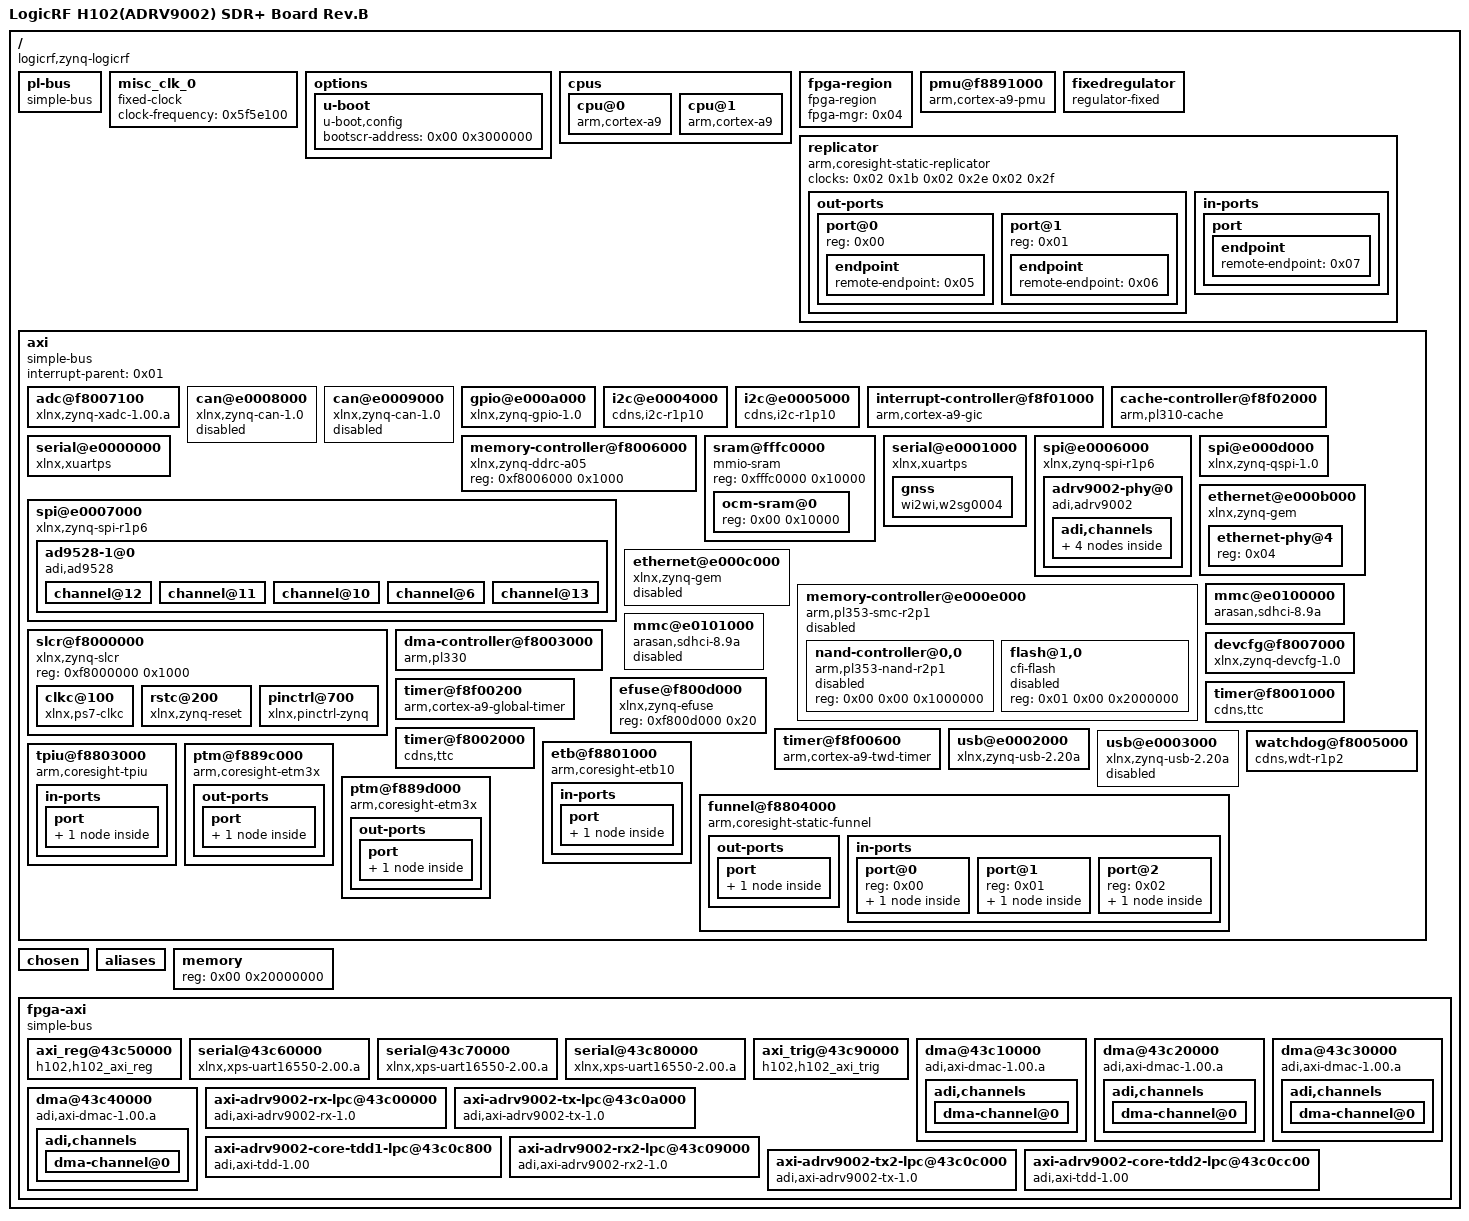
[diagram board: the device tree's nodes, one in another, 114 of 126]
/dts-v1/;

/ {
	#address-cells = <0x01>;
	#size-cells = <0x01>;
	compatible = "logicrf,zynq-logicrf\0xlnx,zynq-7000";
	model = "LogicRF H102(ADRV9002) SDR+ Board Rev.B";
	interrupt-parent = <0x01>;

	pl-bus {
		#address-cells = <0x01>;
		#size-cells = <0x01>;
		compatible = "simple-bus";
		ranges;
		phandle = <0x1b>;
	};

	misc_clk_0 {
		#clock-cells = <0x00>;
		clock-frequency = <0x5f5e100>;
		compatible = "fixed-clock";
		phandle = <0x15>;
	};

	options {

		u-boot {
			compatible = "u-boot,config";
			bootscr-address = <0x00 0x3000000>;
		};
	};

	cpus {
		#address-cells = <0x01>;
		#size-cells = <0x00>;

		cpu@0 {
			compatible = "arm,cortex-a9";
			device_type = "cpu";
			reg = <0x00>;
			clocks = <0x02 0x03>;
			clock-latency = <0x3e8>;
			cpu0-supply = <0x03>;
			operating-points = <0xa2c2b 0xf4240 0x51616 0xf4240>;
			phandle = <0x11>;
		};

		cpu@1 {
			compatible = "arm,cortex-a9";
			device_type = "cpu";
			reg = <0x01>;
			clocks = <0x02 0x03>;
			phandle = <0x13>;
		};
	};

	fpga-region {
		compatible = "fpga-region";
		fpga-mgr = <0x04>;
		#address-cells = <0x01>;
		#size-cells = <0x01>;
		ranges;
		phandle = <0x1c>;
	};

	pmu@f8891000 {
		compatible = "arm,cortex-a9-pmu";
		interrupts = <0x00 0x05 0x04 0x00 0x06 0x04>;
		interrupt-parent = <0x01>;
		reg = <0xf8891000 0x1000 0xf8893000 0x1000>;
	};

	fixedregulator {
		compatible = "regulator-fixed";
		regulator-name = "VCCPINT";
		regulator-min-microvolt = <0xf4240>;
		regulator-max-microvolt = <0xf4240>;
		regulator-boot-on;
		regulator-always-on;
		phandle = <0x03>;
	};

	replicator {
		compatible = "arm,coresight-static-replicator";
		clocks = <0x02 0x1b 0x02 0x2e 0x02 0x2f>;
		clock-names = "apb_pclk\0dbg_trc\0dbg_apb";

		out-ports {
			#address-cells = <0x01>;
			#size-cells = <0x00>;

			port@0 {
				reg = <0x00>;

				endpoint {
					remote-endpoint = <0x05>;
					phandle = <0x0d>;
				};
			};

			port@1 {
				reg = <0x01>;

				endpoint {
					remote-endpoint = <0x06>;
					phandle = <0x0c>;
				};
			};
		};

		in-ports {

			port {

				endpoint {
					remote-endpoint = <0x07>;
					phandle = <0x0e>;
				};
			};
		};
	};

	axi {
		bootph-all;
		compatible = "simple-bus";
		#address-cells = <0x01>;
		#size-cells = <0x01>;
		interrupt-parent = <0x01>;
		ranges;
		phandle = <0x1d>;

		adc@f8007100 {
			compatible = "xlnx,zynq-xadc-1.00.a";
			reg = <0xf8007100 0x20>;
			interrupts = <0x00 0x07 0x04>;
			interrupt-parent = <0x01>;
			clocks = <0x02 0x0c>;
			phandle = <0x1e>;
		};

		can@e0008000 {
			compatible = "xlnx,zynq-can-1.0";
			status = "disabled";
			clocks = <0x02 0x13 0x02 0x24>;
			clock-names = "can_clk\0pclk";
			reg = <0xe0008000 0x1000>;
			interrupts = <0x00 0x1c 0x04>;
			interrupt-parent = <0x01>;
			tx-fifo-depth = <0x40>;
			rx-fifo-depth = <0x40>;
			phandle = <0x1f>;
		};

		can@e0009000 {
			compatible = "xlnx,zynq-can-1.0";
			status = "disabled";
			clocks = <0x02 0x14 0x02 0x25>;
			clock-names = "can_clk\0pclk";
			reg = <0xe0009000 0x1000>;
			interrupts = <0x00 0x33 0x04>;
			interrupt-parent = <0x01>;
			tx-fifo-depth = <0x40>;
			rx-fifo-depth = <0x40>;
			phandle = <0x20>;
		};

		gpio@e000a000 {
			compatible = "xlnx,zynq-gpio-1.0";
			#gpio-cells = <0x02>;
			clocks = <0x02 0x2a>;
			gpio-controller;
			interrupt-controller;
			#interrupt-cells = <0x02>;
			interrupt-parent = <0x01>;
			interrupts = <0x00 0x14 0x04>;
			reg = <0xe000a000 0x1000>;
			emio-gpio-width = <0x40>;
			gpio-mask-high = <0x00>;
			gpio-mask-low = <0x5600>;
			phandle = <0x08>;
		};

		i2c@e0004000 {
			compatible = "cdns,i2c-r1p10";
			status = "okay";
			clocks = <0x02 0x26>;
			interrupt-parent = <0x01>;
			interrupts = <0x00 0x19 0x04>;
			clock-frequency = <0x61a80>;
			reg = <0xe0004000 0x1000>;
			#address-cells = <0x01>;
			#size-cells = <0x00>;
			phandle = <0x21>;
		};

		i2c@e0005000 {
			compatible = "cdns,i2c-r1p10";
			status = "okay";
			clocks = <0x02 0x27>;
			interrupt-parent = <0x01>;
			interrupts = <0x00 0x30 0x04>;
			clock-frequency = <0x61a80>;
			reg = <0xe0005000 0x1000>;
			#address-cells = <0x01>;
			#size-cells = <0x00>;
			phandle = <0x22>;
		};

		interrupt-controller@f8f01000 {
			compatible = "arm,cortex-a9-gic";
			#interrupt-cells = <0x03>;
			interrupt-controller;
			reg = <0xf8f01000 0x1000 0xf8f00100 0x100>;
			phandle = <0x01>;
		};

		cache-controller@f8f02000 {
			compatible = "arm,pl310-cache";
			reg = <0xf8f02000 0x1000>;
			interrupts = <0x00 0x02 0x04>;
			arm,data-latency = <0x03 0x02 0x02>;
			arm,tag-latency = <0x02 0x02 0x02>;
			cache-unified;
			cache-level = <0x02>;
			phandle = <0x23>;
		};

		memory-controller@f8006000 {
			compatible = "xlnx,zynq-ddrc-a05";
			reg = <0xf8006000 0x1000>;
			phandle = <0x24>;
		};

		sram@fffc0000 {
			compatible = "mmio-sram";
			reg = <0xfffc0000 0x10000>;
			#address-cells = <0x01>;
			#size-cells = <0x01>;
			ranges = <0x00 0xfffc0000 0x10000>;
			phandle = <0x25>;

			ocm-sram@0 {
				reg = <0x00 0x10000>;
			};
		};

		serial@e0000000 {
			compatible = "xlnx,xuartps\0cdns,uart-r1p8";
			status = "okay";
			clocks = <0x02 0x17 0x02 0x28>;
			clock-names = "uart_clk\0pclk";
			reg = <0xe0000000 0x1000>;
			interrupts = <0x00 0x1b 0x04>;
			cts-override;
			device_type = "serial";
			port-number = <0x04>;
			phandle = <0x26>;
		};

		serial@e0001000 {
			compatible = "xlnx,xuartps\0cdns,uart-r1p8";
			status = "okay";
			clocks = <0x02 0x18 0x02 0x29>;
			clock-names = "uart_clk\0pclk";
			reg = <0xe0001000 0x1000>;
			interrupts = <0x00 0x32 0x04>;
			cts-override;
			device_type = "serial";
			port-number = <0x05>;
			phandle = <0x27>;

			gnss {
				compatible = "wi2wi,w2sg0004";
				phandle = <0x28>;
			};
		};

		spi@e0006000 {
			compatible = "xlnx,zynq-spi-r1p6";
			reg = <0xe0006000 0x1000>;
			status = "okay";
			interrupt-parent = <0x01>;
			interrupts = <0x00 0x1a 0x04>;
			clocks = <0x02 0x19 0x02 0x22>;
			clock-names = "ref_clk\0pclk";
			#address-cells = <0x01>;
			#size-cells = <0x00>;
			is-decoded-cs = <0x00>;
			num-cs = <0x01>;
			phandle = <0x29>;

			adrv9002-phy@0 {
				compatible = "adi,adrv9002";
				reg = <0x00>;
				interrupt-parent = <0x08>;
				interrupts = <0x62 0x01>;
				spi-max-frequency = <0x1312d00>;
				clocks = <0x09 0x0c>;
				clock-names = "adrv9002_ext_refclk";
				clock-output-names = "rx1_sampl_clk\0tx1_sampl_clk\0tdd1_intf_clk\0rx2_sampl_clk\0tx2_sampl_clk\0tdd2_intf_clk";
				#clock-cells = <0x01>;
				reset-gpios = <0x08 0x64 0x01>;
				phandle = <0x16>;

				adi,channels {
					#address-cells = <0x01>;
					#size-cells = <0x00>;

					rx@0 {
						reg = <0x00>;
						adi,port = <0x00>;
						orx-gpios = <0x08 0x56 0x00>;
						phandle = <0x2a>;
					};

					rx@1 {
						reg = <0x01>;
						adi,port = <0x00>;
						orx-gpios = <0x08 0x57 0x00>;
						phandle = <0x2b>;
					};

					tx@0 {
						reg = <0x00>;
						adi,port = <0x01>;
					};

					tx@1 {
						reg = <0x01>;
						adi,port = <0x01>;
					};
				};
			};
		};

		spi@e0007000 {
			compatible = "xlnx,zynq-spi-r1p6";
			reg = <0xe0007000 0x1000>;
			status = "okay";
			interrupt-parent = <0x01>;
			interrupts = <0x00 0x31 0x04>;
			clocks = <0x02 0x1a 0x02 0x23>;
			clock-names = "ref_clk\0pclk";
			#address-cells = <0x01>;
			#size-cells = <0x00>;
			is-decoded-cs = <0x00>;
			num-cs = <0x03>;
			phandle = <0x2c>;

			ad9528-1@0 {
				compatible = "adi,ad9528";
				reg = <0x00>;
				#address-cells = <0x01>;
				#size-cells = <0x00>;
				spi-max-frequency = <0x989680>;
				clock-output-names = "ad9528-1_out0\0ad9528-1_out1\0ad9528-1_out2\0ad9528-1_out3\0ad9528-1_out4\0ad9528-1_out5\0ad9528-1_out6\0ad9528-1_out7\0ad9528-1_out8\0ad9528-1_out9\0ad9528-1_out10\0ad9528-1_out11\0ad9528-1_out12\0ad9528-1_out13";
				#clock-cells = <0x01>;
				adi,vcxo-freq = <0x5f5e100>;
				adi,refa-enable;
				adi,refa-diff-rcv-enable;
				adi,refa-r-div = <0x0a>;
				adi,refb-enable;
				adi,refb-r-div = <0x01>;
				adi,ref-mode = <0x03>;
				adi,pll1-feedback-div = <0x0a>;
				adi,pll1-charge-pump-current-nA = <0x1770>;
				adi,pll2-vco-div-m1 = <0x03>;
				adi,pll2-n2-div = <0x0c>;
				adi,pll2-r1-div = <0x01>;
				adi,pll2-charge-pump-current-nA = <0xda23c>;
				adi,sysref-src = <0x02>;
				adi,sysref-pattern-mode = <0x01>;
				adi,sysref-k-div = <0x200>;
				adi,sysref-request-enable;
				adi,sysref-nshot-mode = <0x03>;
				adi,sysref-request-trigger-mode = <0x00>;
				adi,rpole2 = <0x00>;
				adi,rzero = <0x07>;
				adi,cpole1 = <0x02>;
				adi,status-mon-pin0-function-select = <0x02>;
				adi,status-mon-pin1-function-select = <0x03>;
				reset-gpios = <0x08 0x65 0x00>;
				phandle = <0x09>;

				channel@12 {
					reg = <0x0c>;
					adi,extended-name = "DEV_CLK";
					adi,driver-mode = <0x00>;
					adi,divider-phase = <0x00>;
					adi,channel-divider = <0x04>;
					adi,signal-source = <0x00>;
					phandle = <0x2d>;
				};

				channel@11 {
					reg = <0x0b>;
					adi,extended-name = "MCS_CLK";
					adi,driver-mode = <0x00>;
					adi,divider-phase = <0x00>;
					adi,channel-divider = <0x04>;
					adi,signal-source = <0x02>;
					phandle = <0x2e>;
				};

				channel@10 {
					reg = <0x0a>;
					adi,extended-name = "FPGA_CLK";
					adi,driver-mode = <0x00>;
					adi,divider-phase = <0x00>;
					adi,channel-divider = <0x04>;
					adi,signal-source = <0x00>;
					phandle = <0x2f>;
				};

				channel@6 {
					reg = <0x06>;
					adi,extended-name = "FPGA_REFCLK";
					adi,driver-mode = <0x00>;
					adi,divider-phase = <0x00>;
					adi,channel-divider = <0x0c>;
					adi,signal-source = <0x00>;
					phandle = <0x30>;
				};

				channel@13 {
					reg = <0x0d>;
					adi,extended-name = "EXT_CLK";
					adi,driver-mode = <0x00>;
					adi,divider-phase = <0x00>;
					adi,channel-divider = <0x0c>;
					adi,signal-source = <0x00>;
					phandle = <0x31>;
				};
			};
		};

		spi@e000d000 {
			compatible = "xlnx,zynq-qspi-1.0";
			reg = <0xe000d000 0x1000>;
			interrupt-parent = <0x01>;
			interrupts = <0x00 0x13 0x04>;
			clocks = <0x02 0x0a 0x02 0x2b>;
			clock-names = "ref_clk\0pclk";
			status = "okay";
			#address-cells = <0x01>;
			#size-cells = <0x00>;
			is-dual = <0x01>;
			num-cs = <0x01>;
			spi-rx-bus-width = <0x08>;
			spi-tx-bus-width = <0x08>;
			phandle = <0x32>;
		};

		ethernet@e000b000 {
			compatible = "xlnx,zynq-gem\0cdns,gem";
			reg = <0xe000b000 0x1000>;
			status = "okay";
			interrupts = <0x00 0x16 0x04>;
			clocks = <0x02 0x1e 0x02 0x1e 0x02 0x0d>;
			clock-names = "pclk\0hclk\0tx_clk";
			#address-cells = <0x01>;
			#size-cells = <0x00>;
			enet-reset = <0x08 0x2e 0x00>;
			phy-mode = "rgmii-id";
			xlnx,ptp-enet-clock = <0x69f6bcb>;
			phy-handle = <0x0a>;
			phandle = <0x33>;

			ethernet-phy@4 {
				reg = <0x04>;
				phandle = <0x0a>;
			};
		};

		ethernet@e000c000 {
			compatible = "xlnx,zynq-gem\0cdns,gem";
			reg = <0xe000c000 0x1000>;
			status = "disabled";
			interrupts = <0x00 0x2d 0x04>;
			clocks = <0x02 0x1f 0x02 0x1f 0x02 0x0e>;
			clock-names = "pclk\0hclk\0tx_clk";
			#address-cells = <0x01>;
			#size-cells = <0x00>;
			phandle = <0x34>;
		};

		memory-controller@e000e000 {
			compatible = "arm,pl353-smc-r2p1\0arm,primecell";
			reg = <0xe000e000 0x1000>;
			status = "disabled";
			clock-names = "memclk\0apb_pclk";
			clocks = <0x02 0x0b 0x02 0x2c>;
			ranges = <0x00 0x00 0xe1000000 0x1000000 0x01 0x00 0xe2000000 0x2000000 0x02 0x00 0xe4000000 0x2000000>;
			#address-cells = <0x02>;
			#size-cells = <0x01>;
			interrupt-parent = <0x01>;
			interrupts = <0x00 0x12 0x04>;
			phandle = <0x35>;

			nand-controller@0,0 {
				compatible = "arm,pl353-nand-r2p1";
				reg = <0x00 0x00 0x1000000>;
				status = "disabled";
				phandle = <0x36>;
			};

			flash@1,0 {
				status = "disabled";
				compatible = "cfi-flash";
				reg = <0x01 0x00 0x2000000>;
				phandle = <0x37>;
			};
		};

		mmc@e0100000 {
			compatible = "arasan,sdhci-8.9a";
			status = "okay";
			clock-names = "clk_xin\0clk_ahb";
			clocks = <0x02 0x15 0x02 0x20>;
			interrupt-parent = <0x01>;
			interrupts = <0x00 0x18 0x04>;
			reg = <0xe0100000 0x1000>;
			xlnx,has-cd = <0x00>;
			xlnx,has-power = <0x00>;
			xlnx,has-wp = <0x00>;
			phandle = <0x38>;
		};

		mmc@e0101000 {
			compatible = "arasan,sdhci-8.9a";
			status = "disabled";
			clock-names = "clk_xin\0clk_ahb";
			clocks = <0x02 0x16 0x02 0x21>;
			interrupt-parent = <0x01>;
			interrupts = <0x00 0x2f 0x04>;
			reg = <0xe0101000 0x1000>;
			phandle = <0x39>;
		};

		slcr@f8000000 {
			bootph-all;
			#address-cells = <0x01>;
			#size-cells = <0x01>;
			compatible = "xlnx,zynq-slcr\0syscon\0simple-mfd";
			reg = <0xf8000000 0x1000>;
			ranges;
			phandle = <0x0b>;

			clkc@100 {
				bootph-all;
				#clock-cells = <0x01>;
				compatible = "xlnx,ps7-clkc";
				fclk-enable = <0x0f>;
				clock-output-names = "armpll\0ddrpll\0iopll\0cpu_6or4x\0cpu_3or2x\0cpu_2x\0cpu_1x\0ddr2x\0ddr3x\0dci\0lqspi\0smc\0pcap\0gem0\0gem1\0fclk0\0fclk1\0fclk2\0fclk3\0can0\0can1\0sdio0\0sdio1\0uart0\0uart1\0spi0\0spi1\0dma\0usb0_aper\0usb1_aper\0gem0_aper\0gem1_aper\0sdio0_aper\0sdio1_aper\0spi0_aper\0spi1_aper\0can0_aper\0can1_aper\0i2c0_aper\0i2c1_aper\0uart0_aper\0uart1_aper\0gpio_aper\0lqspi_aper\0smc_aper\0swdt\0dbg_trc\0dbg_apb";
				reg = <0x100 0x100>;
				ps-clk-frequency = <0x1fca055>;
				phandle = <0x02>;
			};

			rstc@200 {
				compatible = "xlnx,zynq-reset";
				reg = <0x200 0x48>;
				#reset-cells = <0x01>;
				syscon = <0x0b>;
				phandle = <0x3a>;
			};

			pinctrl@700 {
				compatible = "xlnx,pinctrl-zynq";
				reg = <0x700 0x200>;
				syscon = <0x0b>;
				phandle = <0x3b>;
			};
		};

		dma-controller@f8003000 {
			compatible = "arm,pl330\0arm,primecell";
			reg = <0xf8003000 0x1000>;
			interrupt-parent = <0x01>;
			interrupts = <0x00 0x0d 0x04 0x00 0x0e 0x04 0x00 0x0f 0x04 0x00 0x10 0x04 0x00 0x11 0x04 0x00 0x28 0x04 0x00 0x29 0x04 0x00 0x2a 0x04 0x00 0x2b 0x04>;
			#dma-cells = <0x01>;
			clocks = <0x02 0x1b>;
			clock-names = "apb_pclk";
			phandle = <0x3c>;
		};

		devcfg@f8007000 {
			compatible = "xlnx,zynq-devcfg-1.0";
			reg = <0xf8007000 0x100>;
			interrupt-parent = <0x01>;
			interrupts = <0x00 0x08 0x04>;
			clocks = <0x02 0x0c 0x02 0x0f 0x02 0x10 0x02 0x11 0x02 0x12>;
			clock-names = "ref_clk\0fclk0\0fclk1\0fclk2\0fclk3";
			syscon = <0x0b>;
			phandle = <0x04>;
		};

		efuse@f800d000 {
			compatible = "xlnx,zynq-efuse";
			reg = <0xf800d000 0x20>;
			phandle = <0x3d>;
		};

		timer@f8f00200 {
			compatible = "arm,cortex-a9-global-timer";
			reg = <0xf8f00200 0x20>;
			interrupts = <0x01 0x0b 0x301>;
			interrupt-parent = <0x01>;
			clocks = <0x02 0x04>;
			phandle = <0x3e>;
		};

		timer@f8001000 {
			interrupt-parent = <0x01>;
			interrupts = <0x00 0x0a 0x04 0x00 0x0b 0x04 0x00 0x0c 0x04>;
			compatible = "cdns,ttc";
			clocks = <0x02 0x06>;
			reg = <0xf8001000 0x1000>;
			phandle = <0x3f>;
		};

		timer@f8002000 {
			interrupt-parent = <0x01>;
			interrupts = <0x00 0x25 0x04 0x00 0x26 0x04 0x00 0x27 0x04>;
			compatible = "cdns,ttc";
			clocks = <0x02 0x06>;
			reg = <0xf8002000 0x1000>;
			phandle = <0x40>;
		};

		timer@f8f00600 {
			bootph-all;
			interrupt-parent = <0x01>;
			interrupts = <0x01 0x0d 0x301>;
			compatible = "arm,cortex-a9-twd-timer";
			reg = <0xf8f00600 0x20>;
			clocks = <0x02 0x04>;
			phandle = <0x41>;
		};

		usb@e0002000 {
			compatible = "xlnx,zynq-usb-2.20a\0chipidea,usb2";
			status = "okay";
			clocks = <0x02 0x1c>;
			interrupt-parent = <0x01>;
			interrupts = <0x00 0x15 0x04>;
			reg = <0xe0002000 0x1000>;
			phy_type = "ulpi";
			usb-reset = <0x08 0x2f 0x00>;
			phandle = <0x42>;
		};

		usb@e0003000 {
			compatible = "xlnx,zynq-usb-2.20a\0chipidea,usb2";
			status = "disabled";
			clocks = <0x02 0x1d>;
			interrupt-parent = <0x01>;
			interrupts = <0x00 0x2c 0x04>;
			reg = <0xe0003000 0x1000>;
			phy_type = "ulpi";
			phandle = <0x43>;
		};

		watchdog@f8005000 {
			clocks = <0x02 0x2d>;
			compatible = "cdns,wdt-r1p2";
			interrupt-parent = <0x01>;
			interrupts = <0x00 0x09 0x01>;
			reg = <0xf8005000 0x1000>;
			timeout-sec = <0x0a>;
			phandle = <0x44>;
		};

		etb@f8801000 {
			compatible = "arm,coresight-etb10\0arm,primecell";
			reg = <0xf8801000 0x1000>;
			clocks = <0x02 0x1b 0x02 0x2e 0x02 0x2f>;
			clock-names = "apb_pclk\0dbg_trc\0dbg_apb";

			in-ports {

				port {

					endpoint {
						remote-endpoint = <0x0c>;
						phandle = <0x06>;
					};
				};
			};
		};

		tpiu@f8803000 {
			compatible = "arm,coresight-tpiu\0arm,primecell";
			reg = <0xf8803000 0x1000>;
			clocks = <0x02 0x1b 0x02 0x2e 0x02 0x2f>;
			clock-names = "apb_pclk\0dbg_trc\0dbg_apb";

			in-ports {

				port {

					endpoint {
						remote-endpoint = <0x0d>;
						phandle = <0x05>;
					};
				};
			};
		};

		funnel@f8804000 {
			compatible = "arm,coresight-static-funnel\0arm,primecell";
			reg = <0xf8804000 0x1000>;
			clocks = <0x02 0x1b 0x02 0x2e 0x02 0x2f>;
			clock-names = "apb_pclk\0dbg_trc\0dbg_apb";

			out-ports {

				port {

					endpoint {
						remote-endpoint = <0x0e>;
						phandle = <0x07>;
					};
				};
			};

			in-ports {
				#address-cells = <0x01>;
				#size-cells = <0x00>;

				port@0 {
					reg = <0x00>;

					endpoint {
						remote-endpoint = <0x0f>;
						phandle = <0x12>;
					};
				};

				port@1 {
					reg = <0x01>;

					endpoint {
						remote-endpoint = <0x10>;
						phandle = <0x14>;
					};
				};

				port@2 {
					reg = <0x02>;

					endpoint {
						phandle = <0x45>;
					};
				};
			};
		};

		ptm@f889c000 {
			compatible = "arm,coresight-etm3x\0arm,primecell";
			reg = <0xf889c000 0x1000>;
			clocks = <0x02 0x1b 0x02 0x2e 0x02 0x2f>;
			clock-names = "apb_pclk\0dbg_trc\0dbg_apb";
			cpu = <0x11>;

			out-ports {

				port {

					endpoint {
						remote-endpoint = <0x12>;
						phandle = <0x0f>;
					};
				};
			};
		};

		ptm@f889d000 {
			compatible = "arm,coresight-etm3x\0arm,primecell";
			reg = <0xf889d000 0x1000>;
			clocks = <0x02 0x1b 0x02 0x2e 0x02 0x2f>;
			clock-names = "apb_pclk\0dbg_trc\0dbg_apb";
			cpu = <0x13>;

			out-ports {

				port {

					endpoint {
						remote-endpoint = <0x14>;
						phandle = <0x10>;
					};
				};
			};
		};
	};

	chosen {
		bootargs = "console=ttyPS0,115200 earlycon root=/dev/mmcblk0p2 ro rootwait";
		stdout-path = "serial0:115200n8";
	};

	aliases {
		ethernet0 = "/axi/ethernet@e000b000";
		i2c0 = "/axi/i2c@e0004000";
		i2c1 = "/axi/i2c@e0005000";
		serial0 = "/axi/serial@e0000000";
		serial1 = "/axi/serial@e0001000";
		serial2 = "/fpga-axi/serial@43c60000";
		serial3 = "/fpga-axi/serial@43c70000";
		serial4 = "/fpga-axi/serial@43c80000";
		spi0 = "/axi/spi@e000d000";
		spi1 = "/axi/spi@e0006000";
		spi2 = "/axi/spi@e0007000";
	};

	memory {
		device_type = "memory";
		reg = <0x00 0x20000000>;
	};

	fpga-axi {
		compatible = "simple-bus";
		#address-cells = <0x01>;
		#size-cells = <0x01>;
		ranges;
		phandle = <0x46>;

		axi_reg@43c50000 {
			clock-names = "s00_axi_aclk";
			clocks = <0x02 0x0f>;
			compatible = "h102,h102_axi_reg";
			reg = <0x43c50000 0x10000>;
			xlnx,s00-axi-addr-width = <0x0c>;
			xlnx,s00-axi-data-width = <0x20>;
			phandle = <0x47>;
		};

		serial@43c60000 {
			clock-frequency = <0x5f5e100>;
			clock-names = "s_axi_aclk";
			clocks = <0x02 0x0f>;
			compatible = "xlnx,xps-uart16550-2.00.a\0ns16550a";
			current-speed = <0x1c200>;
			device_type = "serial";
			interrupt-names = "ip2intc_irpt";
			interrupt-parent = <0x01>;
			interrupts = <0x00 0x21 0x04>;
			port-number = <0x00>;
			reg = <0x43c60000 0x10000>;
			reg-offset = <0x1000>;
			reg-shift = <0x02>;
			xlnx,external-xin-clk-hz = <0x17d7840>;
			xlnx,external-xin-clk-hz-d = <0x19>;
			xlnx,has-external-rclk = <0x00>;
			xlnx,has-external-xin = <0x00>;
			xlnx,is-a-16550 = <0x01>;
			xlnx,s-axi-aclk-freq-hz-d = "100.0";
			xlnx,sim-device = "VERSAL_AI_CORE_ES1";
			xlnx,use-modem-ports = <0x01>;
			xlnx,use-user-ports = <0x01>;
			phandle = <0x48>;
		};

		serial@43c70000 {
			clock-frequency = <0x5f5e100>;
			clock-names = "s_axi_aclk";
			clocks = <0x02 0x0f>;
			compatible = "xlnx,xps-uart16550-2.00.a\0ns16550a";
			current-speed = <0x1c200>;
			device_type = "serial";
			interrupt-names = "ip2intc_irpt";
			interrupt-parent = <0x01>;
			interrupts = <0x00 0x22 0x04>;
			port-number = <0x02>;
			reg = <0x43c70000 0x10000>;
			reg-offset = <0x1000>;
			reg-shift = <0x02>;
			xlnx,external-xin-clk-hz = <0x17d7840>;
			xlnx,external-xin-clk-hz-d = <0x19>;
			xlnx,has-external-rclk = <0x00>;
			xlnx,has-external-xin = <0x00>;
			xlnx,is-a-16550 = <0x01>;
			xlnx,s-axi-aclk-freq-hz-d = "100.0";
			xlnx,sim-device = "VERSAL_AI_CORE_ES1";
			xlnx,use-modem-ports = <0x01>;
			xlnx,use-user-ports = <0x01>;
			phandle = <0x49>;
		};

		serial@43c80000 {
			clock-frequency = <0x5f5e100>;
			clock-names = "s_axi_aclk";
			clocks = <0x02 0x0f>;
			compatible = "xlnx,xps-uart16550-2.00.a\0ns16550a";
			current-speed = <0x1c200>;
			device_type = "serial";
			interrupt-names = "ip2intc_irpt";
			interrupt-parent = <0x01>;
			interrupts = <0x00 0x23 0x04>;
			port-number = <0x03>;
			reg = <0x43c80000 0x10000>;
			reg-offset = <0x1000>;
			reg-shift = <0x02>;
			xlnx,external-xin-clk-hz = <0x17d7840>;
			xlnx,external-xin-clk-hz-d = <0x19>;
			xlnx,has-external-rclk = <0x00>;
			xlnx,has-external-xin = <0x00>;
			xlnx,is-a-16550 = <0x01>;
			xlnx,s-axi-aclk-freq-hz-d = "100.0";
			xlnx,sim-device = "VERSAL_AI_CORE_ES1";
			xlnx,use-modem-ports = <0x01>;
			xlnx,use-user-ports = <0x01>;
			phandle = <0x4a>;
		};

		axi_trig@43c90000 {
			clock-names = "s00_axi_aclk";
			clocks = <0x02 0x0f>;
			compatible = "h102,h102_axi_trig";
			reg = <0x43c90000 0x10000>;
			xlnx,s00-axi-addr-width = <0x0c>;
			xlnx,s00-axi-data-width = <0x20>;
			phandle = <0x4b>;
		};

		dma@43c10000 {
			compatible = "adi,axi-dmac-1.00.a";
			reg = <0x43c10000 0x10000>;
			#dma-cells = <0x01>;
			interrupts = <0x00 0x1d 0x04>;
			clock-names = "s_axi_aclk\0m_dest_axi_aclk\0fifo_wr_clk";
			clocks = <0x02 0x0f 0x02 0x10 0x15>;
			phandle = <0x17>;

			adi,channels {
				#size-cells = <0x00>;
				#address-cells = <0x01>;

				dma-channel@0 {
					reg = <0x00>;
					adi,source-bus-width = <0x40>;
					adi,source-bus-type = <0x02>;
					adi,destination-bus-width = <0x40>;
					adi,destination-bus-type = <0x00>;
				};
			};
		};

		dma@43c20000 {
			compatible = "adi,axi-dmac-1.00.a";
			reg = <0x43c20000 0x10000>;
			#dma-cells = <0x01>;
			interrupts = <0x00 0x1e 0x04>;
			clock-names = "s_axi_aclk\0m_dest_axi_aclk\0fifo_wr_clk";
			clocks = <0x02 0x0f 0x02 0x10 0x15>;
			phandle = <0x19>;

			adi,channels {
				#size-cells = <0x00>;
				#address-cells = <0x01>;

				dma-channel@0 {
					reg = <0x00>;
					adi,source-bus-width = <0x40>;
					adi,source-bus-type = <0x02>;
					adi,destination-bus-width = <0x40>;
					adi,destination-bus-type = <0x00>;
				};
			};
		};

		dma@43c30000 {
			compatible = "adi,axi-dmac-1.00.a";
			reg = <0x43c30000 0x10000>;
			#dma-cells = <0x01>;
			interrupts = <0x00 0x1f 0x04>;
			clock-names = "s_axi_aclk\0m_src_axi_aclk\0m_axis_aclk";
			clocks = <0x02 0x0f 0x02 0x10 0x15>;
			phandle = <0x18>;

			adi,channels {
				#size-cells = <0x00>;
				#address-cells = <0x01>;

				dma-channel@0 {
					reg = <0x00>;
					adi,source-bus-width = <0x40>;
					adi,source-bus-type = <0x00>;
					adi,destination-bus-width = <0x40>;
					adi,destination-bus-type = <0x02>;
				};
			};
		};

		dma@43c40000 {
			compatible = "adi,axi-dmac-1.00.a";
			reg = <0x43c40000 0x10000>;
			#dma-cells = <0x01>;
			interrupts = <0x00 0x20 0x04>;
			clock-names = "s_axi_aclk\0m_src_axi_aclk\0m_axis_aclk";
			clocks = <0x02 0x0f 0x02 0x10 0x15>;
			phandle = <0x1a>;

			adi,channels {
				#size-cells = <0x00>;
				#address-cells = <0x01>;

				dma-channel@0 {
					reg = <0x00>;
					adi,source-bus-width = <0x40>;
					adi,source-bus-type = <0x00>;
					adi,destination-bus-width = <0x40>;
					adi,destination-bus-type = <0x02>;
				};
			};
		};

		axi-adrv9002-rx-lpc@43c00000 {
			compatible = "adi,axi-adrv9002-rx-1.0";
			reg = <0x43c00000 0x6000>;
			clocks = <0x16 0x00>;
			dmas = <0x17 0x00>;
			dma-names = "rx";
			spibus-connected = <0x16>;
			phandle = <0x4c>;
		};

		axi-adrv9002-tx-lpc@43c0a000 {
			compatible = "adi,axi-adrv9002-tx-1.0";
			reg = <0x43c0a000 0x2000>;
			clocks = <0x16 0x01>;
			clock-names = "sampl_clk";
			dmas = <0x18 0x00>;
			dma-names = "tx";
			adi,axi-dds-default-scale = <0x800>;
			adi,axi-dds-default-frequency = <0x1e8480>;
			phandle = <0x4d>;
		};

		axi-adrv9002-core-tdd1-lpc@43c0c800 {
			compatible = "adi,axi-tdd-1.00";
			reg = <0x43c0c800 0x400>;
			clocks = <0x02 0x10 0x16 0x02>;
			clock-names = "s_axi_aclk\0intf_clk";
			label = "axi-core-tdd-1";
			phandle = <0x4e>;
		};

		axi-adrv9002-rx2-lpc@43c09000 {
			compatible = "adi,axi-adrv9002-rx2-1.0";
			reg = <0x43c09000 0x1000>;
			clocks = <0x16 0x03>;
			clock-names = "sampl_clk";
			dmas = <0x19 0x00>;
			dma-names = "rx";
			phandle = <0x4f>;
		};

		axi-adrv9002-tx2-lpc@43c0c000 {
			compatible = "adi,axi-adrv9002-tx-1.0";
			reg = <0x43c0c000 0x2000>;
			clocks = <0x16 0x04>;
			clock-names = "sampl_clk";
			dmas = <0x1a 0x00>;
			dma-names = "tx";
			adi,axi-dds-default-scale = <0x800>;
			adi,axi-dds-default-frequency = <0x1e8480>;
			phandle = <0x50>;
		};

		axi-adrv9002-core-tdd2-lpc@43c0cc00 {
			compatible = "adi,axi-tdd-1.00";
			reg = <0x43c0cc00 0x400>;
			clocks = <0x02 0x10 0x16 0x05>;
			clock-names = "s_axi_aclk\0intf_clk";
			label = "axi-core-tdd-2";
			phandle = <0x51>;
		};
	};

	__symbols__ {
		amba_pl = "/pl-bus";
		misc_clk_0 = "/misc_clk_0";
		cpu0 = "/cpus/cpu@0";
		cpu1 = "/cpus/cpu@1";
		fpga_full = "/fpga-region";
		regulator_vccpint = "/fixedregulator";
		replicator_out_port0 = "/replicator/out-ports/port@0/endpoint";
		replicator_out_port1 = "/replicator/out-ports/port@1/endpoint";
		replicator_in_port0 = "/replicator/in-ports/port/endpoint";
		amba = "/axi";
		adc = "/axi/adc@f8007100";
		can0 = "/axi/can@e0008000";
		can1 = "/axi/can@e0009000";
		gpio0 = "/axi/gpio@e000a000";
		i2c0 = "/axi/i2c@e0004000";
		i2c1 = "/axi/i2c@e0005000";
		intc = "/axi/interrupt-controller@f8f01000";
		L2 = "/axi/cache-controller@f8f02000";
		mc = "/axi/memory-controller@f8006000";
		ocm = "/axi/sram@fffc0000";
		uart0 = "/axi/serial@e0000000";
		uart1 = "/axi/serial@e0001000";
		gnss = "/axi/serial@e0001000/gnss";
		spi0 = "/axi/spi@e0006000";
		adc0_adrv9002 = "/axi/spi@e0006000/adrv9002-phy@0";
		rx0 = "/axi/spi@e0006000/adrv9002-phy@0/adi,channels/rx@0";
		rx1 = "/axi/spi@e0006000/adrv9002-phy@0/adi,channels/rx@1";
		spi1 = "/axi/spi@e0007000";
		clk0_ad9528 = "/axi/spi@e0007000/ad9528-1@0";
		ad9528_0_c12 = "/axi/spi@e0007000/ad9528-1@0/channel@12";
		ad9528_0_c11 = "/axi/spi@e0007000/ad9528-1@0/channel@11";
		ad9528_0_c10 = "/axi/spi@e0007000/ad9528-1@0/channel@10";
		ad9528_0_c6 = "/axi/spi@e0007000/ad9528-1@0/channel@6";
		ad9528_0_c13 = "/axi/spi@e0007000/ad9528-1@0/channel@13";
		qspi = "/axi/spi@e000d000";
		gem0 = "/axi/ethernet@e000b000";
		ethernet_phy = "/axi/ethernet@e000b000/ethernet-phy@4";
		gem1 = "/axi/ethernet@e000c000";
		smcc = "/axi/memory-controller@e000e000";
		nfc0 = "/axi/memory-controller@e000e000/nand-controller@0,0";
		nor0 = "/axi/memory-controller@e000e000/flash@1,0";
		sdhci0 = "/axi/mmc@e0100000";
		sdhci1 = "/axi/mmc@e0101000";
		slcr = "/axi/slcr@f8000000";
		clkc = "/axi/slcr@f8000000/clkc@100";
		rstc = "/axi/slcr@f8000000/rstc@200";
		pinctrl0 = "/axi/slcr@f8000000/pinctrl@700";
		dmac_s = "/axi/dma-controller@f8003000";
		devcfg = "/axi/devcfg@f8007000";
		efuse = "/axi/efuse@f800d000";
		global_timer = "/axi/timer@f8f00200";
		ttc0 = "/axi/timer@f8001000";
		ttc1 = "/axi/timer@f8002000";
		scutimer = "/axi/timer@f8f00600";
		usb0 = "/axi/usb@e0002000";
		usb1 = "/axi/usb@e0003000";
		watchdog0 = "/axi/watchdog@f8005000";
		etb_in_port = "/axi/etb@f8801000/in-ports/port/endpoint";
		tpiu_in_port = "/axi/tpiu@f8803000/in-ports/port/endpoint";
		funnel_out_port = "/axi/funnel@f8804000/out-ports/port/endpoint";
		funnel0_in_port0 = "/axi/funnel@f8804000/in-ports/port@0/endpoint";
		funnel0_in_port1 = "/axi/funnel@f8804000/in-ports/port@1/endpoint";
		funnel0_in_port2 = "/axi/funnel@f8804000/in-ports/port@2/endpoint";
		ptm0_out_port = "/axi/ptm@f889c000/out-ports/port/endpoint";
		ptm1_out_port = "/axi/ptm@f889d000/out-ports/port/endpoint";
		fpga_axi = "/fpga-axi";
		axi_reg = "/fpga-axi/axi_reg@43c50000";
		axi_uart16550_rs232 = "/fpga-axi/serial@43c60000";
		axi_uart16550_rs422 = "/fpga-axi/serial@43c70000";
		axi_uart16550_rs485 = "/fpga-axi/serial@43c80000";
		axi_trig = "/fpga-axi/axi_trig@43c90000";
		rx1_dma = "/fpga-axi/dma@43c10000";
		rx2_dma = "/fpga-axi/dma@43c20000";
		tx1_dma = "/fpga-axi/dma@43c30000";
		tx2_dma = "/fpga-axi/dma@43c40000";
		axi_adrv9002_core_rx1 = "/fpga-axi/axi-adrv9002-rx-lpc@43c00000";
		axi_adrv9002_core_tx1 = "/fpga-axi/axi-adrv9002-tx-lpc@43c0a000";
		axi_adrv9002_core_tdd1 = "/fpga-axi/axi-adrv9002-core-tdd1-lpc@43c0c800";
		axi_adrv9002_core_rx2 = "/fpga-axi/axi-adrv9002-rx2-lpc@43c09000";
		axi_adrv9002_core_tx2 = "/fpga-axi/axi-adrv9002-tx2-lpc@43c0c000";
		axi_adrv9002_core_tdd2 = "/fpga-axi/axi-adrv9002-core-tdd2-lpc@43c0cc00";
	};
};
